# dm648_cslr_pll2_001 register map
Vendor: Texas Instruments
Peripheral module from a debugger description file.
Registers are 32-bit, access not given, reset 0x10802 unless marked. A register's access mark holds for its fields unless they carry their own. Offsets are as the file gives them; lines under a group give offsets from that group; [hi:lo] are bit positions; {n}, {i} and the like mark numbered series; 'fields as' and 'values as' point back to an identical list; <NAME> marks a mode.

## PLL2 — PLL2 Module
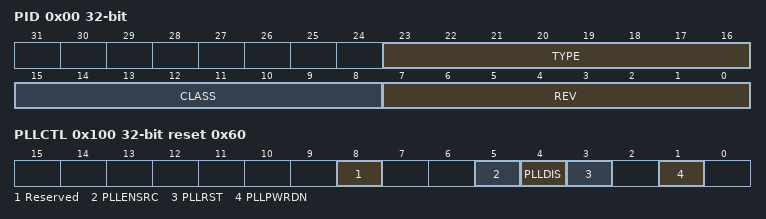
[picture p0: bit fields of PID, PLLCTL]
0x00 PID — PLL Peripheral ID Register
  [23:16] TYPE ro — Peripheral type
  [15:8] CLASS ro — Peripheral class
  [7:0] REV ro — Peripheral revision
0x100 PLLCTL reset 0x60 — PLL Control Register
  [8] Reserved — (access N)
  [5] PLLENSRC rw — PLL Mux Control Source
    0=PLLENBIT (PLLEN Mux is controlled by PLLCTL.PLLEN); 1=PLLENPI (PLLEN Mux is controlled by input pllen_pi)
  [4] PLLDIS rw — PLL enable/disable
    0=ENABLE (PLL Enabled); 1=DISABLE (PLL Disabled)
  [3] PLLRST rw — PLL reset
    0=PLL_IN_RESET (PLL reset asserted); 1=PLL_NOT_IN_RESET (PLL reset not asserted)
  [1] PLLPWRDN rw — PLL Power down
    0=POWERED_DOWN (PLL is powered down, no PLL operation); 1=POWERED_UP (PLL is powered up)
0x110 PLLM reset 0x10 — PLL Multiplier Register
  [5:0] PLLM rw — PLL multiplier
